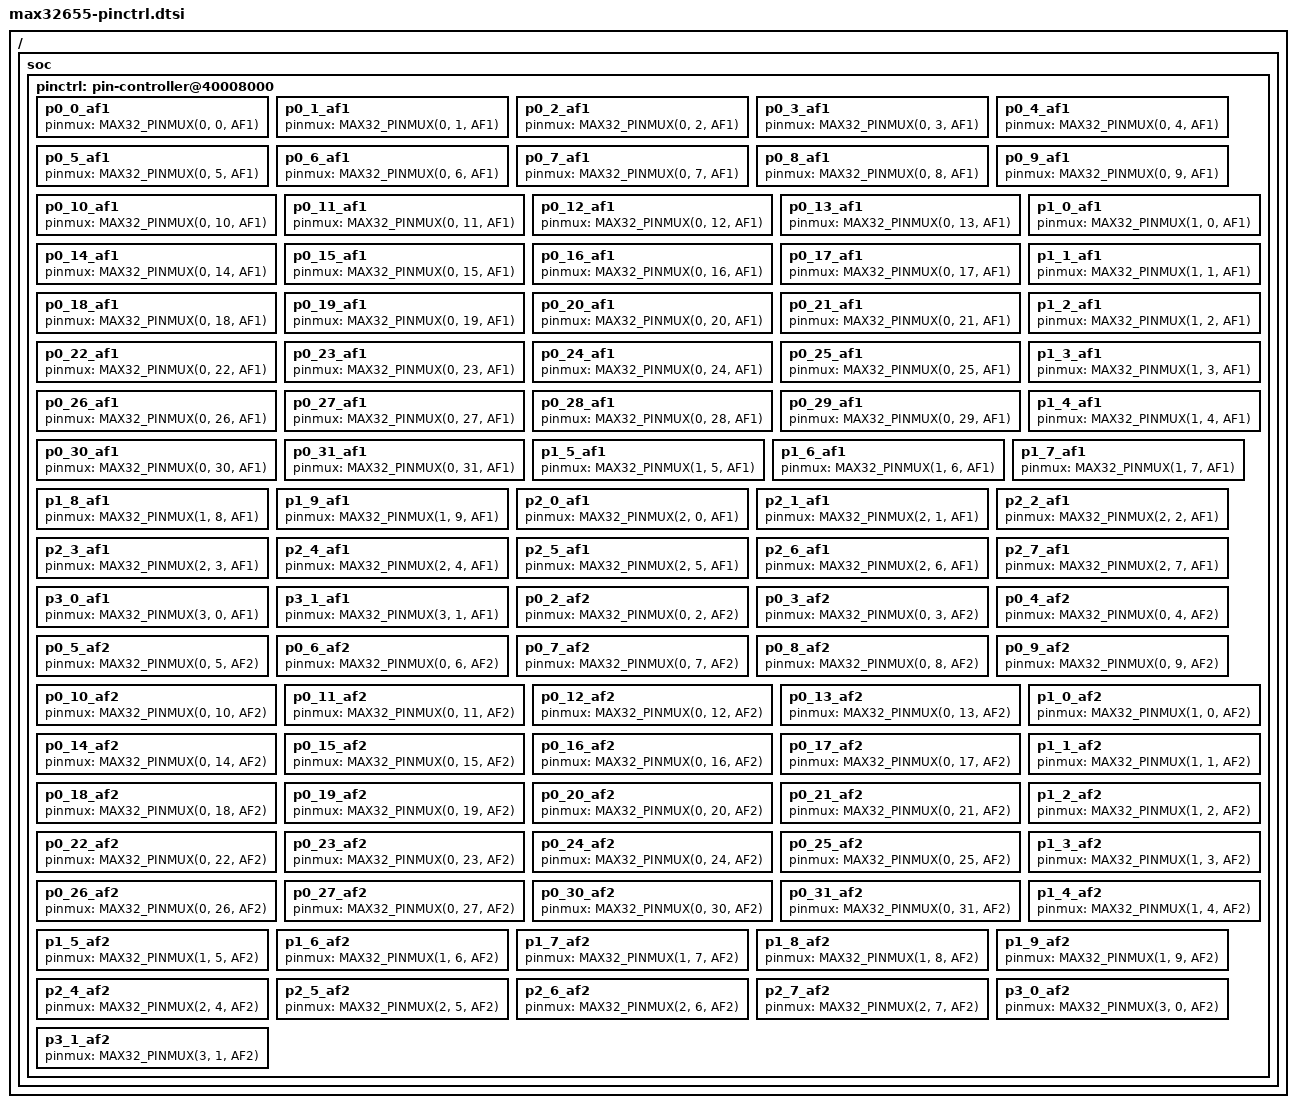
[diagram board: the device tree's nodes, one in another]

#include <zephyr/dt-bindings/pinctrl/max32-pinctrl.h>

/ {
	soc {
		pinctrl: pin-controller@40008000 {

			/omit-if-no-ref/ p0_0_af1:  p0_0_af1  { pinmux = <MAX32_PINMUX(0,  0, AF1)>; };
			/omit-if-no-ref/ p0_1_af1:  p0_1_af1  { pinmux = <MAX32_PINMUX(0,  1, AF1)>; };
			/omit-if-no-ref/ p0_2_af1:  p0_2_af1  { pinmux = <MAX32_PINMUX(0,  2, AF1)>; };
			/omit-if-no-ref/ p0_3_af1:  p0_3_af1  { pinmux = <MAX32_PINMUX(0,  3, AF1)>; };
			/omit-if-no-ref/ p0_4_af1:  p0_4_af1  { pinmux = <MAX32_PINMUX(0,  4, AF1)>; };
			/omit-if-no-ref/ p0_5_af1:  p0_5_af1  { pinmux = <MAX32_PINMUX(0,  5, AF1)>; };
			/omit-if-no-ref/ p0_6_af1:  p0_6_af1  { pinmux = <MAX32_PINMUX(0,  6, AF1)>; };
			/omit-if-no-ref/ p0_7_af1:  p0_7_af1  { pinmux = <MAX32_PINMUX(0,  7, AF1)>; };
			/omit-if-no-ref/ p0_8_af1:  p0_8_af1  { pinmux = <MAX32_PINMUX(0,  8, AF1)>; };
			/omit-if-no-ref/ p0_9_af1:  p0_9_af1  { pinmux = <MAX32_PINMUX(0,  9, AF1)>; };
			/omit-if-no-ref/ p0_10_af1: p0_10_af1 { pinmux = <MAX32_PINMUX(0, 10, AF1)>; };
			/omit-if-no-ref/ p0_11_af1: p0_11_af1 { pinmux = <MAX32_PINMUX(0, 11, AF1)>; };
			/omit-if-no-ref/ p0_12_af1: p0_12_af1 { pinmux = <MAX32_PINMUX(0, 12, AF1)>; };
			/omit-if-no-ref/ p0_13_af1: p0_13_af1 { pinmux = <MAX32_PINMUX(0, 13, AF1)>; };
			/omit-if-no-ref/ p0_14_af1: p0_14_af1 { pinmux = <MAX32_PINMUX(0, 14, AF1)>; };
			/omit-if-no-ref/ p0_15_af1: p0_15_af1 { pinmux = <MAX32_PINMUX(0, 15, AF1)>; };
			/omit-if-no-ref/ p0_16_af1: p0_16_af1 { pinmux = <MAX32_PINMUX(0, 16, AF1)>; };
			/omit-if-no-ref/ p0_17_af1: p0_17_af1 { pinmux = <MAX32_PINMUX(0, 17, AF1)>; };
			/omit-if-no-ref/ p0_18_af1: p0_18_af1 { pinmux = <MAX32_PINMUX(0, 18, AF1)>; };
			/omit-if-no-ref/ p0_19_af1: p0_19_af1 { pinmux = <MAX32_PINMUX(0, 19, AF1)>; };
			/omit-if-no-ref/ p0_20_af1: p0_20_af1 { pinmux = <MAX32_PINMUX(0, 20, AF1)>; };
			/omit-if-no-ref/ p0_21_af1: p0_21_af1 { pinmux = <MAX32_PINMUX(0, 21, AF1)>; };
			/omit-if-no-ref/ p0_22_af1: p0_22_af1 { pinmux = <MAX32_PINMUX(0, 22, AF1)>; };
			/omit-if-no-ref/ p0_23_af1: p0_23_af1 { pinmux = <MAX32_PINMUX(0, 23, AF1)>; };
			/omit-if-no-ref/ p0_24_af1: p0_24_af1 { pinmux = <MAX32_PINMUX(0, 24, AF1)>; };
			/omit-if-no-ref/ p0_25_af1: p0_25_af1 { pinmux = <MAX32_PINMUX(0, 25, AF1)>; };
			/omit-if-no-ref/ p0_26_af1: p0_26_af1 { pinmux = <MAX32_PINMUX(0, 26, AF1)>; };
			/omit-if-no-ref/ p0_27_af1: p0_27_af1 { pinmux = <MAX32_PINMUX(0, 27, AF1)>; };
			/omit-if-no-ref/ p0_28_af1: p0_28_af1 { pinmux = <MAX32_PINMUX(0, 28, AF1)>; };
			/omit-if-no-ref/ p0_29_af1: p0_29_af1 { pinmux = <MAX32_PINMUX(0, 29, AF1)>; };
			/omit-if-no-ref/ p0_30_af1: p0_30_af1 { pinmux = <MAX32_PINMUX(0, 30, AF1)>; };
			/omit-if-no-ref/ p0_31_af1: p0_31_af1 { pinmux = <MAX32_PINMUX(0, 31, AF1)>; };
			/omit-if-no-ref/ p1_0_af1:  p1_0_af1  { pinmux = <MAX32_PINMUX(1,  0, AF1)>; };
			/omit-if-no-ref/ p1_1_af1:  p1_1_af1  { pinmux = <MAX32_PINMUX(1,  1, AF1)>; };
			/omit-if-no-ref/ p1_2_af1:  p1_2_af1  { pinmux = <MAX32_PINMUX(1,  2, AF1)>; };
			/omit-if-no-ref/ p1_3_af1:  p1_3_af1  { pinmux = <MAX32_PINMUX(1,  3, AF1)>; };
			/omit-if-no-ref/ p1_4_af1:  p1_4_af1  { pinmux = <MAX32_PINMUX(1,  4, AF1)>; };
			/omit-if-no-ref/ p1_5_af1:  p1_5_af1  { pinmux = <MAX32_PINMUX(1,  5, AF1)>; };
			/omit-if-no-ref/ p1_6_af1:  p1_6_af1  { pinmux = <MAX32_PINMUX(1,  6, AF1)>; };
			/omit-if-no-ref/ p1_7_af1:  p1_7_af1  { pinmux = <MAX32_PINMUX(1,  7, AF1)>; };
			/omit-if-no-ref/ p1_8_af1:  p1_8_af1  { pinmux = <MAX32_PINMUX(1,  8, AF1)>; };
			/omit-if-no-ref/ p1_9_af1:  p1_9_af1  { pinmux = <MAX32_PINMUX(1,  9, AF1)>; };
			/omit-if-no-ref/ p2_0_af1:  p2_0_af1  { pinmux = <MAX32_PINMUX(2,  0, AF1)>; };
			/omit-if-no-ref/ p2_1_af1:  p2_1_af1  { pinmux = <MAX32_PINMUX(2,  1, AF1)>; };
			/omit-if-no-ref/ p2_2_af1:  p2_2_af1  { pinmux = <MAX32_PINMUX(2,  2, AF1)>; };
			/omit-if-no-ref/ p2_3_af1:  p2_3_af1  { pinmux = <MAX32_PINMUX(2,  3, AF1)>; };
			/omit-if-no-ref/ p2_4_af1:  p2_4_af1  { pinmux = <MAX32_PINMUX(2,  4, AF1)>; };
			/omit-if-no-ref/ p2_5_af1:  p2_5_af1  { pinmux = <MAX32_PINMUX(2,  5, AF1)>; };
			/omit-if-no-ref/ p2_6_af1:  p2_6_af1  { pinmux = <MAX32_PINMUX(2,  6, AF1)>; };
			/omit-if-no-ref/ p2_7_af1:  p2_7_af1  { pinmux = <MAX32_PINMUX(2,  7, AF1)>; };
			/omit-if-no-ref/ p3_0_af1:  p3_0_af1  { pinmux = <MAX32_PINMUX(3,  0, AF1)>; };
			/omit-if-no-ref/ p3_1_af1:  p3_1_af1  { pinmux = <MAX32_PINMUX(3,  1, AF1)>; };

			/omit-if-no-ref/ p0_2_af2:  p0_2_af2  { pinmux = <MAX32_PINMUX(0,  2, AF2)>; };
			/omit-if-no-ref/ p0_3_af2:  p0_3_af2  { pinmux = <MAX32_PINMUX(0,  3, AF2)>; };
			/omit-if-no-ref/ p0_4_af2:  p0_4_af2  { pinmux = <MAX32_PINMUX(0,  4, AF2)>; };
			/omit-if-no-ref/ p0_5_af2:  p0_5_af2  { pinmux = <MAX32_PINMUX(0,  5, AF2)>; };
			/omit-if-no-ref/ p0_6_af2:  p0_6_af2  { pinmux = <MAX32_PINMUX(0,  6, AF2)>; };
			/omit-if-no-ref/ p0_7_af2:  p0_7_af2  { pinmux = <MAX32_PINMUX(0,  7, AF2)>; };
			/omit-if-no-ref/ p0_8_af2:  p0_8_af2  { pinmux = <MAX32_PINMUX(0,  8, AF2)>; };
			/omit-if-no-ref/ p0_9_af2:  p0_9_af2  { pinmux = <MAX32_PINMUX(0,  9, AF2)>; };
			/omit-if-no-ref/ p0_10_af2: p0_10_af2 { pinmux = <MAX32_PINMUX(0, 10, AF2)>; };
			/omit-if-no-ref/ p0_11_af2: p0_11_af2 { pinmux = <MAX32_PINMUX(0, 11, AF2)>; };
			/omit-if-no-ref/ p0_12_af2: p0_12_af2 { pinmux = <MAX32_PINMUX(0, 12, AF2)>; };
			/omit-if-no-ref/ p0_13_af2: p0_13_af2 { pinmux = <MAX32_PINMUX(0, 13, AF2)>; };
			/omit-if-no-ref/ p0_14_af2: p0_14_af2 { pinmux = <MAX32_PINMUX(0, 14, AF2)>; };
			/omit-if-no-ref/ p0_15_af2: p0_15_af2 { pinmux = <MAX32_PINMUX(0, 15, AF2)>; };
			/omit-if-no-ref/ p0_16_af2: p0_16_af2 { pinmux = <MAX32_PINMUX(0, 16, AF2)>; };
			/omit-if-no-ref/ p0_17_af2: p0_17_af2 { pinmux = <MAX32_PINMUX(0, 17, AF2)>; };
			/omit-if-no-ref/ p0_18_af2: p0_18_af2 { pinmux = <MAX32_PINMUX(0, 18, AF2)>; };
			/omit-if-no-ref/ p0_19_af2: p0_19_af2 { pinmux = <MAX32_PINMUX(0, 19, AF2)>; };
			/omit-if-no-ref/ p0_20_af2: p0_20_af2 { pinmux = <MAX32_PINMUX(0, 20, AF2)>; };
			/omit-if-no-ref/ p0_21_af2: p0_21_af2 { pinmux = <MAX32_PINMUX(0, 21, AF2)>; };
			/omit-if-no-ref/ p0_22_af2: p0_22_af2 { pinmux = <MAX32_PINMUX(0, 22, AF2)>; };
			/omit-if-no-ref/ p0_23_af2: p0_23_af2 { pinmux = <MAX32_PINMUX(0, 23, AF2)>; };
			/omit-if-no-ref/ p0_24_af2: p0_24_af2 { pinmux = <MAX32_PINMUX(0, 24, AF2)>; };
			/omit-if-no-ref/ p0_25_af2: p0_25_af2 { pinmux = <MAX32_PINMUX(0, 25, AF2)>; };
			/omit-if-no-ref/ p0_26_af2: p0_26_af2 { pinmux = <MAX32_PINMUX(0, 26, AF2)>; };
			/omit-if-no-ref/ p0_27_af2: p0_27_af2 { pinmux = <MAX32_PINMUX(0, 27, AF2)>; };
			/omit-if-no-ref/ p0_30_af2: p0_30_af2 { pinmux = <MAX32_PINMUX(0, 30, AF2)>; };
			/omit-if-no-ref/ p0_31_af2: p0_31_af2 { pinmux = <MAX32_PINMUX(0, 31, AF2)>; };
			/omit-if-no-ref/ p1_0_af2:  p1_0_af2  { pinmux = <MAX32_PINMUX(1,  0, AF2)>; };
			/omit-if-no-ref/ p1_1_af2:  p1_1_af2  { pinmux = <MAX32_PINMUX(1,  1, AF2)>; };
			/omit-if-no-ref/ p1_2_af2:  p1_2_af2  { pinmux = <MAX32_PINMUX(1,  2, AF2)>; };
			/omit-if-no-ref/ p1_3_af2:  p1_3_af2  { pinmux = <MAX32_PINMUX(1,  3, AF2)>; };
			/omit-if-no-ref/ p1_4_af2:  p1_4_af2  { pinmux = <MAX32_PINMUX(1,  4, AF2)>; };
			/omit-if-no-ref/ p1_5_af2:  p1_5_af2  { pinmux = <MAX32_PINMUX(1,  5, AF2)>; };
			/omit-if-no-ref/ p1_6_af2:  p1_6_af2  { pinmux = <MAX32_PINMUX(1,  6, AF2)>; };
			/omit-if-no-ref/ p1_7_af2:  p1_7_af2  { pinmux = <MAX32_PINMUX(1,  7, AF2)>; };
			/omit-if-no-ref/ p1_8_af2:  p1_8_af2  { pinmux = <MAX32_PINMUX(1,  8, AF2)>; };
			/omit-if-no-ref/ p1_9_af2:  p1_9_af2  { pinmux = <MAX32_PINMUX(1,  9, AF2)>; };
			/omit-if-no-ref/ p2_4_af2:  p2_4_af2  { pinmux = <MAX32_PINMUX(2,  4, AF2)>; };
			/omit-if-no-ref/ p2_5_af2:  p2_5_af2  { pinmux = <MAX32_PINMUX(2,  5, AF2)>; };
			/omit-if-no-ref/ p2_6_af2:  p2_6_af2  { pinmux = <MAX32_PINMUX(2,  6, AF2)>; };
			/omit-if-no-ref/ p2_7_af2:  p2_7_af2  { pinmux = <MAX32_PINMUX(2,  7, AF2)>; };
			/omit-if-no-ref/ p3_0_af2:  p3_0_af2  { pinmux = <MAX32_PINMUX(3,  0, AF2)>; };
			/omit-if-no-ref/ p3_1_af2:  p3_1_af2  { pinmux = <MAX32_PINMUX(3,  1, AF2)>; };
		};
	};
};
